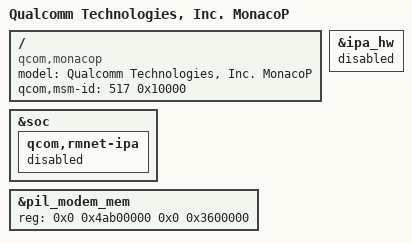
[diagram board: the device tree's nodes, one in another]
#include "monaco.dtsi"

/ {
	model = "Qualcomm Technologies, Inc. MonacoP";
	compatible = "qcom,monacop";
	qcom,msm-id = <517 0x10000>;
};

&soc {
	qcom,rmnet-ipa {
		status = "disabled";
	};
};

&ipa_hw {
	status = "disabled";
};

&pil_modem_mem {
	reg = <0x0 0x4ab00000 0x0 0x3600000>;
};
